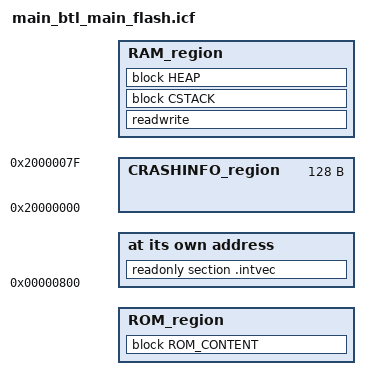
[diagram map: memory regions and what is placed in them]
/*###ICF### Section handled by ICF editor, don't touch! ****/
/*-Editor annotation file-*/
/* IcfEditorFile="$TOOLKIT_DIR$\config\ide\IcfEditor\cortex_v1_0.xml" */
/* Version 4.1.1 */

/*-Specials-*/
define symbol __ICFEDIT_intvec_start__   = 0x00000800;
define symbol __ICFEDIT_crashinfo_size__ = 0x00000080;

/*-Memory Regions-*/
define symbol __ICFEDIT_region_ROM_start__ = 0x00000800;
define symbol __ICFEDIT_region_ROM_end__   = (0x00000800+0x003800-1);
define symbol __ICFEDIT_region_RAM_start__ = 0x20000000;
define symbol __ICFEDIT_region_RAM_end__   = (0x20000000+0x00008000-1);

/*-Sizes-*/
define symbol __ICFEDIT_size_cstack__ = 0x1000;
define symbol __ICFEDIT_size_heap__   = 0x100;
/**** End of ICF editor section. ###ICF###*/

define memory mem with size = 4G;
define region ROM_region   = mem:[from __ICFEDIT_region_ROM_start__   to __ICFEDIT_region_ROM_end__];
define region CRASHINFO_region = mem:[from __ICFEDIT_region_RAM_start__ to (__ICFEDIT_region_RAM_start__+__ICFEDIT_crashinfo_size__-1)];
define region RAM_region   = mem:[from (__ICFEDIT_region_RAM_start__+__ICFEDIT_crashinfo_size__)   to __ICFEDIT_region_RAM_end__];

define block CSTACK    with alignment = 8, size = __ICFEDIT_size_cstack__   { };
define block HEAP      with alignment = 8, size = __ICFEDIT_size_heap__     { };

initialize by copy { readwrite };
do not initialize  { section .noinit };

keep { section .intvec };
place at address mem:__ICFEDIT_intvec_start__ { readonly section .intvec };

define block ROM_CONTENT with fixed order { readonly, readonly section ROM_SIZE};

place in ROM_region   { block ROM_CONTENT };
place in RAM_region   { readwrite,
                        block CSTACK,
                        block HEAP };
